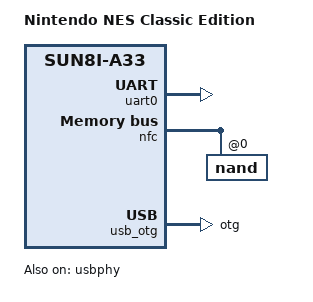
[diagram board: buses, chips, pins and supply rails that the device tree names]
/dts-v1/;
#include "sun8i-a33.dtsi"
#include "sunxi-common-regulators.dtsi"
/ {
	model = "Nintendo NES Classic Edition";
	compatible = "nintendo,nes-classic", "allwinner,sun8i-r16",
		     "allwinner,sun8i-a33";
	aliases {
		serial0 = &uart0;
	};
	chosen {
		stdout-path = "serial0:115200n8";
	};
};
&uart0 {
	pinctrl-names = "default";
	pinctrl-0 = <&uart0_pf_pins>;
	status = "okay";
};
&nfc {
	status = "okay";
	nand@0 {
		reg = <0>;
		allwinner,rb = <0>;
		nand-ecc-mode = "hw";
		nand-ecc-strength = <16>;
		nand-ecc-step-size = <1024>;
	};
};
&usb_otg {
	status = "okay";
	dr_mode = "otg";
};
&usbphy {
	usb1_vbus-supply = <&reg_vcc5v0>;
	status = "okay";
};
